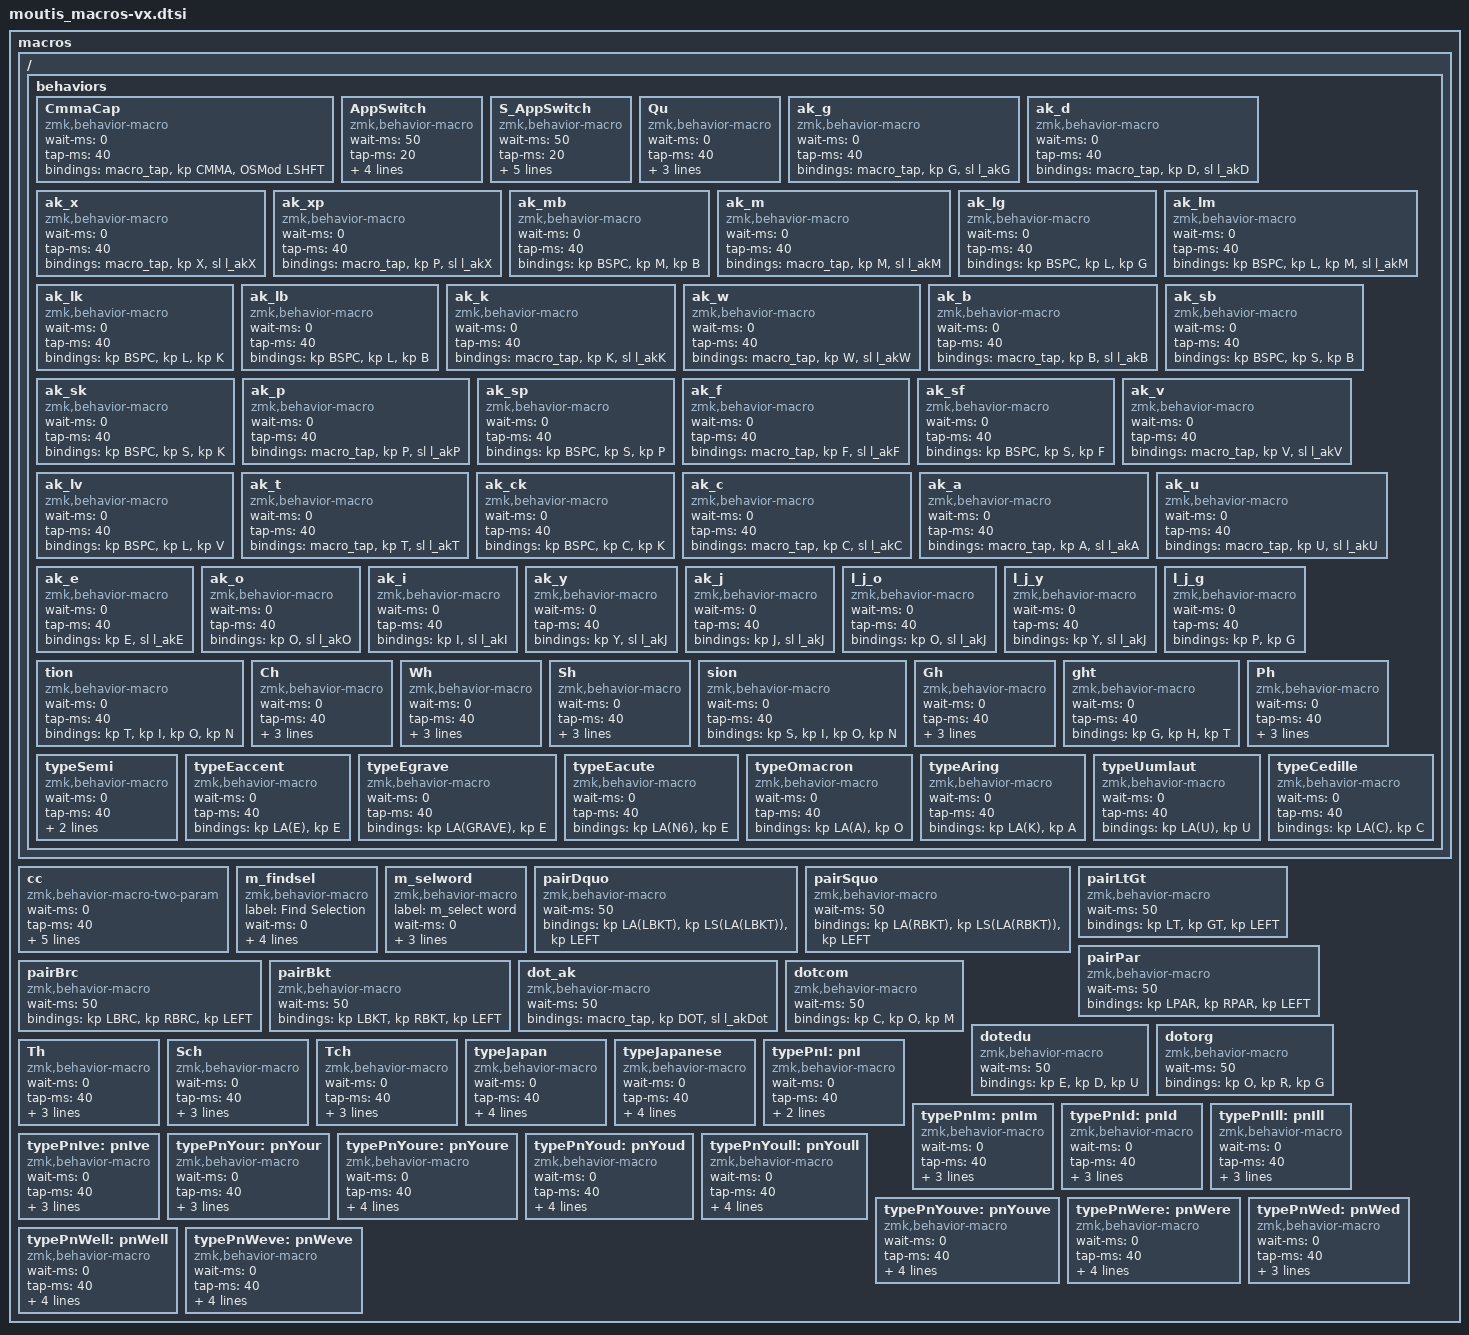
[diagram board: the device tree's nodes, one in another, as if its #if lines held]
 
    macros {

#ifdef COMMA_CAP
     ZMK_MACRO(CmmaCap,
                wait-ms = <0>;
                tap-ms = <40>;
        bindings = <&macro_tap &kp CMMA>
//                  , <&sl l_CCaps>
            , <&OSMod LSHFT>
                    ;
        )

     cc: cc { // comma cap an adaptive key (using sticky layer)
            compatible = "zmk,behavior-macro-two-param";
        #binding-cells = <2>;
                wait-ms = <0>;
                tap-ms = <40>;
        bindings = <&macro_tap &kp BSPC> // delete the comma
            , <&macro_press &kp LSHFT> //
            , <&macro_param_1to1>
            , <&macro_tap &kp MACRO_PLACEHOLDER> // cap the letter
            , <&macro_release &kp LSHFT> //
            , <&macro_param_2to1>
                , <&sl MACRO_PLACEHOLDER> // go to adaptive layer
                   ;
        };
#endif


   ZMK_MACRO(AppSwitch,
            wait-ms = <50>;
            tap-ms = <20>;
        bindings =
                    <&macro_press &kp RGUI>    // leave GUI down to keep menu up
                  , <&macro_tap &kp TAB>       // (use press for repeat)
                  , <&tog l_nav>               // to navigate the app menu
                  , <&macro_pause_for_release> // hold to keep menu up or for repeat ...
                  , <&tog l_nav>               // done navigating
                  , <&macro_tap &skapp LGUI>   // release other GUI after a timeout
                  , <&macro_release &kp RGUI>  // release the previous hold
                  ;
        )
    ZMK_MACRO(S_AppSwitch,
            wait-ms = <50>;
            tap-ms = <20>;
        bindings =
                    <&macro_press &sk RGUI> // leave GUI down to keep menu up
                  , <&macro_press &kp LSHFT> //
                  , <&macro_tap &kp TAB> // just tap for no repeat
                  , <&macro_pause_for_release> // hold for repeat ...
                  , <&macro_release &kp LSHFT> //
                  , <&macro_tap &skapp LGUI> // release other GUI after a timeout
                  , <&macro_release &sk RGUI> // now release the previous hold
                  ;
        )

        m_findsel: m_findsel {
            label = "Find Selection";
            compatible = "zmk,behavior-macro";
            #binding-cells = <0>;
            wait-ms = <0>;
            tap-ms = <40>;
             bindings = <&macro_tap &kp LG(C)>
                    , <&macro_tap &kp LG(F)>
                    , <&macro_tap &kp LG(V)>
                    , <&macro_tap &kp RETURN>
                    , <&macro_tap &kp LG(G)>
                ;
        };

        m_selword: m_selword {
            label = "m_select word";
            compatible = "zmk,behavior-macro";
            #binding-cells = <0>;
            wait-ms = <0>;
            tap-ms = <40>;
            bindings = <&macro_tap &kp LA(LEFT)>
                    , <&macro_tap &kp LS(LA(RIGHT))>
                ;
        };


    ZMK_MACRO(Qu,
                wait-ms = <0>;
                tap-ms = <40>;
        bindings = <&macro_tap &kp Q>
                , <&macro_release &kp LSHFT>
                , <&macro_release &kp RSHFT>
                , <&macro_tap &kp U>
                ;
        )

    pairDquo: pairDquo {
        compatible = "zmk,behavior-macro";
        #binding-cells = <0>;
        wait-ms = <50>; // need to slow this down for some systems.
        bindings = <&kp LA(LBKT) &kp LS(LA(LBKT)) &kp LEFT>
                ;
        };
    pairSquo: pairSquo {
        compatible = "zmk,behavior-macro";
        #binding-cells = <0>;
        wait-ms = <50>; // need to slow this down for some systems.
        bindings = <&kp LA(RBKT) &kp LS(LA(RBKT)) &kp LEFT>
                ;
        };
    pairLtGt: pairLtGt {
        compatible = "zmk,behavior-macro";
        #binding-cells = <0>;
        wait-ms = <50>; // need to slow this down for some systems.
        bindings = <&kp LT &kp GT &kp LEFT>
                ;
        };
    pairPar: pairPar {
        compatible = "zmk,behavior-macro";
        #binding-cells = <0>;
        wait-ms = <50>; // need to slow this down for some systems.
        bindings = <&kp LPAR &kp RPAR &kp LEFT>
                ;
        };
    pairBrc: pairBrc {
        compatible = "zmk,behavior-macro";
        #binding-cells = <0>;
        wait-ms = <50>; // need to slow this down for some systems.
        bindings = <&kp LBRC &kp RBRC &kp LEFT>
                ;
        };
    pairBkt: pairBkt {
        compatible = "zmk,behavior-macro";
        #binding-cells = <0>;
        wait-ms = <50>; // need to slow this down for some systems.
        bindings = <&kp LBKT &kp RBKT &kp LEFT>
                ;
        };
    dot_ak: dot_ak {
        compatible = "zmk,behavior-macro";
        #binding-cells = <0>;
        wait-ms = <50>; // need to slow this down for some systems.
        bindings = <&macro_tap &kp DOT>
                , <&sl l_akDot>;
        };
    dotcom: dotcom {
        compatible = "zmk,behavior-macro";
        #binding-cells = <0>;
        wait-ms = <50>; // need to slow this down for some systems.
        bindings = <&kp C &kp O &kp M>
                ;
        };
    dotedu: dotedu {
        compatible = "zmk,behavior-macro";
        #binding-cells = <0>;
        wait-ms = <50>; // need to slow this down for some systems.
        bindings = <&kp E &kp D &kp U>
                ;
        };
    dotorg: dotorg {
        compatible = "zmk,behavior-macro";
        #binding-cells = <0>;
        wait-ms = <50>; // need to slow this down for some systems.
        bindings = <&kp O &kp R &kp G>
                ;
        };

    ZMK_MACRO(ak_g,
                wait-ms = <0>;
                tap-ms = <40>;
        bindings = <&macro_tap &kp G>
                , <&sl l_akG>;
        )
    ZMK_MACRO(ak_d,
            wait-ms = <0>;
            tap-ms = <40>;
        bindings = <&macro_tap &kp D>
                , <&sl l_akD>;
        )
    ZMK_MACRO(ak_x,
            wait-ms = <0>;
            tap-ms = <40>;
        bindings = <&macro_tap &kp X>
                , <&sl l_akX>;
        )
    ZMK_MACRO(ak_xp,
            wait-ms = <0>;
            tap-ms = <40>;
        bindings = <&macro_tap &kp P>
                , <&sl l_akX>;
        )
    ZMK_MACRO(ak_mb,
            wait-ms = <0>;
            tap-ms = <40>;
        bindings = <&kp BSPC &kp M &kp B>;
        )
    ZMK_MACRO(ak_m,
            wait-ms = <0>;
            tap-ms = <40>;
        bindings = <&macro_tap &kp M>
                , <&sl l_akM>;
        )
    ZMK_MACRO(ak_lg,
            wait-ms = <0>;
            tap-ms = <40>;
        bindings = <&kp BSPC &kp L &kp G>;
        )
    ZMK_MACRO(ak_lm,
            wait-ms = <0>;
            tap-ms = <40>;
        bindings = <&kp BSPC &kp L &kp M>
                    , <&sl l_akM>;
        )
    ZMK_MACRO(ak_lk,
            wait-ms = <0>;
            tap-ms = <40>;
        bindings = <&kp BSPC &kp L &kp K>;
        )
    ZMK_MACRO(ak_lb,
            wait-ms = <0>;
            tap-ms = <40>;
        bindings = <&kp BSPC &kp L &kp B>;
        )
    ZMK_MACRO(ak_k,
            wait-ms = <0>;
            tap-ms = <40>;
        bindings = <&macro_tap &kp K>
                , <&sl l_akK>;
        )
    ZMK_MACRO(ak_w,
            wait-ms = <0>;
            tap-ms = <40>;
        bindings = <&macro_tap &kp W>
                , <&sl l_akW>;
        )
    ZMK_MACRO(ak_b,
            wait-ms = <0>;
            tap-ms = <40>;
        bindings = <&macro_tap &kp B>
                , <&sl l_akB>;
        )
    ZMK_MACRO(ak_sb,
            wait-ms = <0>;
            tap-ms = <40>;
        bindings = <&kp BSPC &kp S &kp B>;
        )
    ZMK_MACRO(ak_sk,
            wait-ms = <0>;
            tap-ms = <40>;
        bindings = <&kp BSPC &kp S &kp K>;
        )
    ZMK_MACRO(ak_p,
            wait-ms = <0>;
            tap-ms = <40>;
        bindings = <&macro_tap &kp P>
                , <&sl l_akP>;
        )
    ZMK_MACRO(ak_sp,
            wait-ms = <0>;
            tap-ms = <40>;
        bindings = <&kp BSPC &kp S &kp P>;
        )
    ZMK_MACRO(ak_f,
            wait-ms = <0>;
            tap-ms = <40>;
        bindings = <&macro_tap &kp F>
                , <&sl l_akF>;
        )
    ZMK_MACRO(ak_sf,
            wait-ms = <0>;
            tap-ms = <40>;
        bindings = <&kp BSPC &kp S &kp F>;
        )
    ZMK_MACRO(ak_v,
            wait-ms = <0>;
            tap-ms = <40>;
        bindings = <&macro_tap &kp V>
                , <&sl l_akV>;
        )
    ZMK_MACRO(ak_lv,
            wait-ms = <0>;
            tap-ms = <40>;
        bindings = <&kp BSPC &kp L &kp V>;
        )

    ZMK_MACRO(ak_t,
            wait-ms = <0>;
            tap-ms = <40>;
        bindings = <&macro_tap &kp T>
                , <&sl l_akT>;
        )
    ZMK_MACRO(ak_ck,
            wait-ms = <0>;
            tap-ms = <40>;
        bindings = <&kp BSPC &kp C &kp K>;
        )
    ZMK_MACRO(ak_c,
            wait-ms = <0>;
            tap-ms = <40>;
        bindings = <&macro_tap &kp C>
                , <&sl l_akC>;
        )
    ZMK_MACRO(ak_a,
            wait-ms = <0>;
            tap-ms = <40>;
        bindings = <&macro_tap &kp A>
                , <&sl l_akA>;
        )
    ZMK_MACRO(ak_u,
            wait-ms = <0>;
            tap-ms = <40>;
        bindings = <&macro_tap &kp U>
                , <&sl l_akU>;
        )
    ZMK_MACRO(ak_e,
            wait-ms = <0>;
            tap-ms = <40>;
        bindings = <&kp E &sl l_akE>;
        )
    ZMK_MACRO(ak_o,
            wait-ms = <0>;
            tap-ms = <40>;
        bindings = <&kp O &sl l_akO>;
        )
    ZMK_MACRO(ak_i,
            wait-ms = <0>;
            tap-ms = <40>;
        bindings = <&kp I &sl l_akI>;
        )
    ZMK_MACRO(ak_y,
            wait-ms = <0>;
            tap-ms = <40>;
        bindings = <&kp Y &sl l_akJ>;
        )
    ZMK_MACRO(ak_j,
            wait-ms = <0>;
            tap-ms = <40>;
        bindings = <&kp J &sl l_akJ>;
        )
    ZMK_MACRO(l_j_o,
            wait-ms = <0>;
            tap-ms = <40>;
        bindings = <&kp O &sl l_akJ>;
        )
    ZMK_MACRO(l_j_y,
            wait-ms = <0>;
            tap-ms = <40>;
        bindings = <&kp Y &sl l_akJ>;
        )
    ZMK_MACRO(l_j_g,
            wait-ms = <0>;
            tap-ms = <40>;
        bindings = <&kp P &kp G>;
        )



#ifdef H_DIGRAPH_COMBOS
    Th: Th {
        compatible = "zmk,behavior-macro";
        #binding-cells = <0>;
        wait-ms = <0>;
        tap-ms = <40>;
        bindings = <&macro_tap &kp T>
            , <&macro_release &kp LSHFT>
            , <&macro_release &kp RSHFT>
            , <&macro_tap &kp H>
            ;
        };
    ZMK_MACRO(tion,
        wait-ms = <0>;
        tap-ms = <40>;
        bindings = <&kp T &kp I &kp O &kp N>
                ;
        )
    ZMK_MACRO(Ch,
        wait-ms = <0>;
        tap-ms = <40>;
        bindings = <&macro_tap &kp C>
                , <&macro_release &kp LSHFT>
                , <&macro_release &kp RSHFT>
                , <&macro_tap &kp H>
                ;
        )
    ZMK_MACRO(Wh,
        wait-ms = <0>;
        tap-ms = <40>;
        bindings = <&macro_tap &kp W>
                , <&macro_release &kp LSHFT>
                , <&macro_release &kp RSHFT>
                , <&macro_tap &kp H>
                ;
        )
    ZMK_MACRO(Sh,
        wait-ms = <0>;
        tap-ms = <40>;
        bindings = <&macro_tap &kp S>
                , <&macro_release &kp LSHFT>
                , <&macro_release &kp RSHFT>
                , <&macro_tap &kp H>
                ;
        )
    ZMK_MACRO(sion,
        wait-ms = <0>;
        tap-ms = <40>;
        bindings = <&kp S &kp I &kp O &kp N>
                ;
        )
    ZMK_MACRO(Gh,
            wait-ms = <0>;
            tap-ms = <40>;
        bindings = <&macro_tap &kp G>
                , <&macro_release &kp LSHFT>
                , <&macro_release &kp RSHFT>
                , <&macro_tap &kp H>
                ;
        )
    ZMK_MACRO(ght,
            wait-ms = <0>;
            tap-ms = <40>;
        bindings = <&kp G &kp H &kp T>
                ;
        )
    ZMK_MACRO(Ph,
            wait-ms = <0>;
            tap-ms = <40>;
        bindings = <&macro_tap &kp P>
                , <&macro_release &kp LSHFT>
                , <&macro_release &kp RSHFT>
                , <&macro_tap &kp H>
                ;
        )


        Sch: Sch {
            compatible = "zmk,behavior-macro";
            #binding-cells = <0>;
            wait-ms = <0>;
            tap-ms = <40>;
            bindings = <&macro_tap &kp S>
                    , <&macro_release &kp LSHFT>
                    , <&macro_release &kp RSHFT>
                    , <&macro_tap &kp C &kp H>
                ;
        };
        Tch: Tch {
            compatible = "zmk,behavior-macro";
            #binding-cells = <0>;
            wait-ms = <0>;
            tap-ms = <40>;
            bindings = <&macro_tap &kp T>
                    , <&macro_release &kp LSHFT>
                    , <&macro_release &kp RSHFT>
                    , <&macro_tap &kp C &kp H>
                ;
        };
#endif

    ZMK_MACRO(typeSemi,
            wait-ms = <0>;
            tap-ms = <40>;
        bindings = <&macro_release &kp LSHFT>
                , <&macro_tap &kp SEMICOLON>
                ;
        )
    ZMK_MACRO(typeEaccent,
            wait-ms = <0>;
            tap-ms = <40>;
        bindings = <&kp LA(E) &kp E>
                ;
        )
    ZMK_MACRO(typeEgrave,
            wait-ms = <0>;
            tap-ms = <40>;
        bindings = <&kp LA(GRAVE) &kp E>
                ;
        )
    ZMK_MACRO(typeEacute,
            wait-ms = <0>;
            tap-ms = <40>;
        bindings = <&kp LA(N6) &kp E>
                ;
        )
    ZMK_MACRO(typeOmacron,
            wait-ms = <0>;
            tap-ms = <40>;
        bindings = <&kp LA(A) &kp O>
                ;
        )
    ZMK_MACRO(typeAring,
            wait-ms = <0>;
            tap-ms = <40>;
        bindings = <&kp LA(K) &kp A>
                ;
        )
    ZMK_MACRO(typeUumlaut,
            wait-ms = <0>;
            tap-ms = <40>;
        bindings = <&kp LA(U) &kp U>
                ;
        )
    ZMK_MACRO(typeCedille,
            wait-ms = <0>;
            tap-ms = <40>;
        bindings = <&kp LA(C) &kp C>
                ;
        )
        typeJapan: typeJapan {
            compatible = "zmk,behavior-macro";
            #binding-cells = <0>;
            wait-ms = <0>;
            tap-ms = <40>;
            bindings = <&macro_press &kp LSHFT>
                    , <&macro_tap &kp J>
                    , <&macro_release &kp LSHFT>
                    , <&macro_release &kp RSHFT>
                    , <&macro_tap &kp A &kp P &kp A &kp N &kp SPACE>
                ;
        };
        typeJapanese: typeJapanese {
            compatible = "zmk,behavior-macro";
            #binding-cells = <0>;
            wait-ms = <0>;
            tap-ms = <40>;
            bindings = <&macro_press &kp LSHFT>
                    , <&macro_tap &kp J>
                    , <&macro_release &kp LSHFT>
                    , <&macro_release &kp RSHFT>
                    , <&macro_tap &kp A &kp P &kp A &kp N &kp E &kp S &kp E &kp SPACE>
                ;
        };


#ifdef EN_PRONOUN_COMBOS
// Pronouns
        typePnI: pnI {
            compatible = "zmk,behavior-macro";
            #binding-cells = <0>;
            wait-ms = <0>;
            tap-ms = <40>;
            bindings = <&macro_tap &kp LS(I)>
                    , <&macro_tap &kp SPACE>
                ;
        };
        typePnIm: pnIm {
            compatible = "zmk,behavior-macro";
            #binding-cells = <0>;
            wait-ms = <0>;
            tap-ms = <40>;
            bindings = <&macro_tap &kp LS(I)>
                    , <&macro_release &kp LSHFT>
                    , <&macro_release &kp RSHFT>
                    , <&macro_tap &kp APOS &kp M &kp SPACE>
                ;
        };
        typePnId: pnId {
            compatible = "zmk,behavior-macro";
            #binding-cells = <0>;
            wait-ms = <0>;
            tap-ms = <40>;
            bindings = <&macro_tap &kp LS(I)>
                    , <&macro_release &kp LSHFT>
                    , <&macro_release &kp RSHFT>
                    , <&macro_tap &kp APOS &kp D &kp SPACE>
                ;
        };
        typePnIll: pnIll {
            compatible = "zmk,behavior-macro";
            #binding-cells = <0>;
            wait-ms = <0>;
            tap-ms = <40>;
            bindings = <&macro_tap &kp LS(I)>
                    , <&macro_release &kp LSHFT>
                    , <&macro_release &kp RSHFT>
                    , <&macro_tap &kp APOS &kp L &kp L &kp SPACE>
                ;
        };
        typePnIve: pnIve {
            compatible = "zmk,behavior-macro";
            #binding-cells = <0>;
            wait-ms = <0>;
            tap-ms = <40>;
            bindings = <&macro_tap &kp LS(I)>
                    , <&macro_release &kp LSHFT>
                    , <&macro_release &kp RSHFT>
                    , <&macro_tap &kp APOS &kp V &kp E &kp SPACE>
                ;
        };
// YOU
        typePnYour: pnYour {
            compatible = "zmk,behavior-macro";
            #binding-cells = <0>;
            wait-ms = <0>;
            tap-ms = <40>;
            bindings = <&macro_tap &kp Y>
                    , <&macro_release &kp LSHFT>
                    , <&macro_release &kp RSHFT>
                    , <&macro_tap &kp O &kp U &kp R &kp SPACE>
                ;
        };
        typePnYoure: pnYoure {
            compatible = "zmk,behavior-macro";
            #binding-cells = <0>;
            wait-ms = <0>;
            tap-ms = <40>;
            bindings = <&macro_tap &kp Y>
                    , <&macro_release &kp LSHFT>
                    , <&macro_release &kp RSHFT>
                    , <&macro_tap &kp O &kp U &kp APOS &kp R &kp E &kp SPACE>
                ;
        };
        typePnYoud: pnYoud {
            compatible = "zmk,behavior-macro";
            #binding-cells = <0>;
            wait-ms = <0>;
            tap-ms = <40>;
            bindings = <&macro_tap &kp Y>
                    , <&macro_release &kp LSHFT>
                    , <&macro_release &kp RSHFT>
                    , <&macro_tap &kp O &kp U &kp APOS &kp D &kp SPACE>
                ;
        };
        typePnYoull: pnYoull {
            compatible = "zmk,behavior-macro";
            #binding-cells = <0>;
            wait-ms = <0>;
            tap-ms = <40>;
            bindings = <&macro_tap &kp Y>
                    , <&macro_release &kp LSHFT>
                    , <&macro_release &kp RSHFT>
                    , <&macro_tap &kp O &kp U &kp APOS &kp L &kp L &kp SPACE>
                ;
        };
        typePnYouve: pnYouve {
            compatible = "zmk,behavior-macro";
            #binding-cells = <0>;
            wait-ms = <0>;
            tap-ms = <40>;
            bindings = <&macro_tap &kp Y>
                    , <&macro_release &kp LSHFT>
                    , <&macro_release &kp RSHFT>
                    , <&macro_tap &kp O &kp U &kp APOS &kp V &kp E &kp SPACE>
                ;
        };
// WE
        typePnWere: pnWere {
            compatible = "zmk,behavior-macro";
            #binding-cells = <0>;
            wait-ms = <0>;
            tap-ms = <40>;
            bindings = <&macro_tap &kp W>
                    , <&macro_release &kp LSHFT>
                    , <&macro_release &kp RSHFT>
                    , <&macro_tap &kp E &kp APOS &kp R &kp E &kp SPACE>
                ;
        };
        typePnWed: pnWed {
            compatible = "zmk,behavior-macro";
            #binding-cells = <0>;
            wait-ms = <0>;
            tap-ms = <40>;
            bindings = <&macro_tap &kp W>
                    , <&macro_release &kp LSHFT>
                    , <&macro_release &kp RSHFT>
                    , <&macro_tap &kp E &kp APOS &kp D &kp SPACE>
                ;
        };
        typePnWell: pnWell {
            compatible = "zmk,behavior-macro";
            #binding-cells = <0>;
            wait-ms = <0>;
            tap-ms = <40>;
            bindings = <&macro_tap &kp W>
                    , <&macro_release &kp LSHFT>
                    , <&macro_release &kp RSHFT>
                    , <&macro_tap &kp E &kp APOS &kp L &kp L &kp SPACE>
                ;
        };
        typePnWeve: pnWeve {
            compatible = "zmk,behavior-macro";
            #binding-cells = <0>;
            wait-ms = <0>;
            tap-ms = <40>;
            bindings = <&macro_tap &kp W>
                    , <&macro_release &kp LSHFT>
                    , <&macro_release &kp RSHFT>
                    , <&macro_tap &kp E &kp APOS &kp V &kp E &kp SPACE>
                ;
        };

#endif // EN_PRONOUN_COMBOS

    };

